# MKS22F12 register map
Vendor: Freescale Semiconductor, Inc.; Series: Kinetis_K; File version: 1.6
CPU: CM4 r0p1, little endian, no MPU, FPU, VTOR, 4 interrupt priority bits
Registers are 32-bit, read-write, reset 0x0 unless marked. A register's access mark holds for its fields unless they carry their own. Offsets are from the block's base; [hi:lo] are bit positions; {n}, {i} and the like mark numbered series; 'fields as' and 'values as' point back to an identical list.

## CRC — Cyclic Redundancy Check
Base 0x40032000; register names take the prefix CRC_
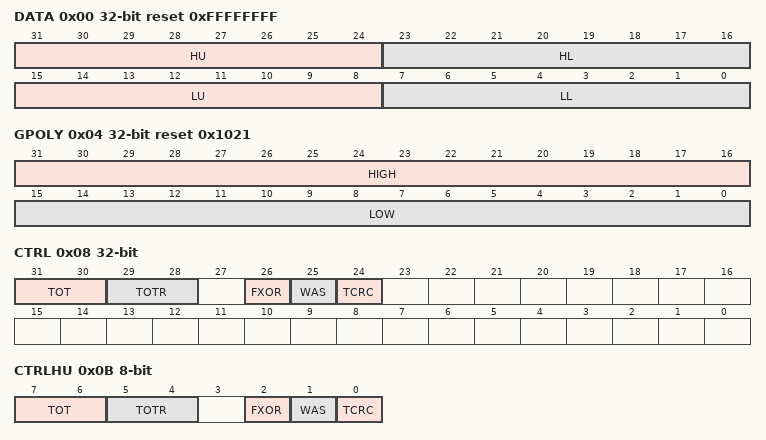
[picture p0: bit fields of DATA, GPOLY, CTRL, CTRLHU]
0x00 DATA reset 0xFFFFFFFF (CRC view) — CRC Data register
  [31:24] HU — CRC High Upper Byte
  [23:16] HL — CRC High Lower Byte
  [15:8] LU — CRC Low Upper Byte
  [7:0] LL — CRC Low Lower Byte
0x00 DATAL 16-bit reset 0xFFFF (CRC view) — CRC_DATAL register.
  [15:0] DATAL — DATAL stores the lower 16 bits of the 16/32 bit CRC
0x00 DATALL 8-bit reset 0xFF (CRC view) — CRC_DATALL register.
  [7:0] DATALL — CRCLL stores the first 8 bits of the 32 bit DATA
0x01 DATALU 8-bit reset 0xFF — CRC_DATALU register.
  [7:0] DATALU — DATALL stores the second 8 bits of the 32 bit CRC
0x02 DATAH 16-bit reset 0xFFFF (CRC view) — CRC_DATAH register.
  [15:0] DATAH — DATAH stores the high 16 bits of the 16/32 bit CRC
0x02 DATAHL 8-bit reset 0xFF (CRC view) — CRC_DATAHL register.
  [7:0] DATAHL — DATAHL stores the third 8 bits of the 32 bit CRC
0x03 DATAHU 8-bit reset 0xFF — CRC_DATAHU register.
  [7:0] DATAHU — DATAHU stores the fourth 8 bits of the 32 bit CRC
0x04 GPOLY reset 0x1021 (CRC view) — CRC Polynomial register
  [31:16] HIGH — High Polynominal Half-word
  [15:0] LOW — Low Polynominal Half-word
0x04 GPOLYL 16-bit reset 0xFFFF (CRC view) — CRC_GPOLYL register.
  [15:0] GPOLYL — POLYL stores the lower 16 bits of the 16/32 bit CRC polynomial value
0x04 GPOLYLL 8-bit reset 0xFF (CRC view) — CRC_GPOLYLL register.
  [7:0] GPOLYLL — POLYLL stores the first 8 bits of the 32 bit CRC
0x05 GPOLYLU 8-bit reset 0xFF — CRC_GPOLYLU register.
  [7:0] GPOLYLU — POLYLL stores the second 8 bits of the 32 bit CRC
0x06 GPOLYH 16-bit reset 0xFFFF (CRC view) — CRC_GPOLYH register.
  [15:0] GPOLYH — POLYH stores the high 16 bits of the 16/32 bit CRC polynomial value
0x06 GPOLYHL 8-bit reset 0xFF (CRC view) — CRC_GPOLYHL register.
  [7:0] GPOLYHL — POLYHL stores the third 8 bits of the 32 bit CRC
0x07 GPOLYHU 8-bit reset 0xFF — CRC_GPOLYHU register.
  [7:0] GPOLYHU — POLYHU stores the fourth 8 bits of the 32 bit CRC
0x08 CTRL — CRC Control register
  [31:30] TOT — Type Of Transpose For Writes
    0=No transposition; 1=Bits in bytes are transposed; bytes are not transposed; 2=Both bits in bytes and bytes are transposed; 3=Only bytes are transposed; no bits in a byte are transposed
  [29:28] TOTR — Type Of Transpose For Read
    values as TOT
  [26] FXOR — Complement Read Of CRC Data Register
    0=No XOR on reading; 1=Invert or complement the read value of the CRC Data register
  [25] WAS — Write CRC Data Register As Seed
    0=Writes to the CRC data register are data values; 1=Writes to the CRC data register are seed values
  [24] TCRC — Width of CRC protocol.
    0=16-bit CRC protocol; 1=32-bit CRC protocol
0x0B CTRLHU 8-bit — CRC_CTRLHU register.
  [7:6] TOT
    0=No Transposition; 1=Bits in bytes are transposed, bytes are not transposed; 2=Both bits in bytes and bytes are transposed; 3=Only bytes are transposed; no bits in a byte are transposed
  [5:4] TOTR
    values as TOT
  [2] FXOR
    0=No XOR on reading; 1=Invert or complement the read value of CRC data register
  [1] WAS
    0=Writes to CRC data register are data values; 1=Writes to CRC data reguster are seed values
  [0] TCRC
    0=16-bit CRC protocol; 1=32-bit CRC protocol

## PIT — Periodic Interrupt Timer
Base 0x40037000; register names take the prefix PIT_
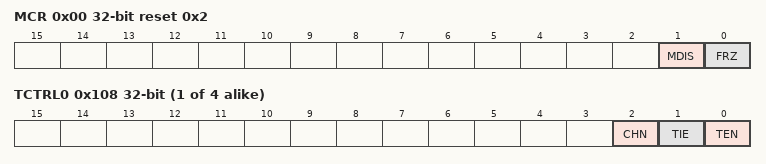
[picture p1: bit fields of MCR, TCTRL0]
0x00 MCR reset 0x2 — PIT Module Control Register
  [1] MDIS — Module Disable - (PIT section)
    0=Clock for standard PIT timers is enabled; 1=Clock for standard PIT timers is disabled
  [0] FRZ — Freeze
    0=Timers continue to run in Debug mode; 1=Timers are stopped in Debug mode
0xE0 LTMR64H ro — PIT Upper Lifetime Timer Register
  [31:0] LTH — Life Timer value
0xE4 LTMR64L ro — PIT Lower Lifetime Timer Register
  [31:0] LTL — Life Timer value
{0x100+0x10*i} LDVAL{i} (i=0..3) — Timer Load Value Register
  [31:0] TSV — Timer Start Value
{0x104+0x10*i} CVAL{i} (i=0..3) ro — Current Timer Value Register
  [31:0] TVL — Current Timer Value
{0x108+0x10*i} TCTRL{i} (i=0..3) — Timer Control Register
  [2] CHN — Chain Mode
    0=Timer is not chained; 1=Timer is chained to previous timer. For example, for Channel 2, if this field is set, Timer 2 is chained to Timer 1.
  [1] TIE — Timer Interrupt Enable
    0=Interrupt requests from Timer n are disabled; 1=Interrupt will be requested whenever TIF is set
  [0] TEN — Timer Enable
    0=Timer n is disabled; 1=Timer n is enabled
{0x10C+0x10*i} TFLG{i} (i=0..3) — Timer Flag Register
  [0] TIF — Timer Interrupt Flag
    0=Timeout has not yet occurred; 1=Timeout has occurred
